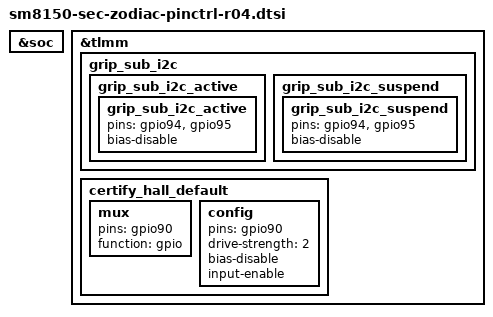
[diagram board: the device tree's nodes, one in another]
/* Copyright (c) 2016-2017, The Linux Foundation. All rights reserved.
 *
 * This program is free software; you can redistribute it and/or modify
 * it under the terms of the GNU General Public License version 2 and
 * only version 2 as published by the Free Software Foundation.
 *
 * This program is distributed in the hope that it will be useful,
 * but WITHOUT ANY WARRANTY; without even the implied warranty of
 * MERCHANTABILITY or FITNESS FOR A PARTICULAR PURPOSE.  See the
 * GNU General Public License for more details.
 */

#include "sm8150-sec-zodiac-pinctrl-common.dtsi"

&soc {
	/* tlmm: pinctrl@03400000 { }; */
};

&tlmm {
	grip_sub_i2c {
		grip_sub_i2c_active: grip_sub_i2c_active {
			grip_sub_i2c_active {
				pins = "gpio94", "gpio95";
				bias-disable;
			};
		};
		grip_sub_i2c_suspend: grip_sub_i2c_suspend {
			grip_sub_i2c_suspend {
				pins = "gpio94", "gpio95";
				bias-disable;
			};
		};
	};

	certify_hall_default: certify_hall_default {
		mux {
			pins = "gpio90";
			function = "gpio";				
		};
		config {
			pins = "gpio90";
			drive-strength = <2>;
			bias-disable;
			input-enable;
		};
	};
};
